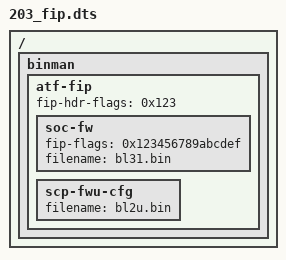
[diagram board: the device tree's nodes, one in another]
// SPDX-License-Identifier: GPL-2.0+
/dts-v1/;

/ {
	#address-cells = <1>;
	#size-cells = <1>;

	binman {
		atf-fip {
			fip-hdr-flags = /bits/ 64 <0x123>;
			soc-fw {
				fip-flags = /bits/ 64 <0x123456789abcdef>;
				filename = "bl31.bin";
			};

			scp-fwu-cfg {
				filename = "bl2u.bin";
			};
		};
	};
};
